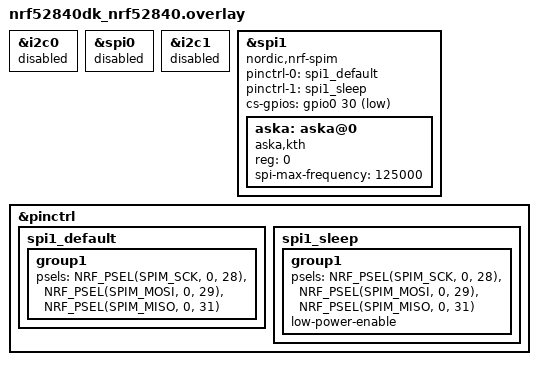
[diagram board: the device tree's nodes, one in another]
// To get started, press Ctrl+Space to bring up the completion menu and view the available nodes.

// You can also use the buttons in the sidebar to perform actions on nodes.
// Actions currently available include:

// * Enabling / disabling the node
// * Adding the bus to a bus
// * Removing the node
// * Connecting ADC channels

// For more help, browse the DeviceTree documentation at https://docs.zephyrproject.org/latest/guides/dts/index.html
// You can also visit the nRF DeviceTree extension documentation at https://docs.nordicsemi.com/bundle/nrf-connect-vscode/page/guides/ncs_configure_app.html#devicetree-support-in-the-extension

&i2c0 { status = "disabled";};
&spi0 { status = "disabled";};
&i2c1 { status = "disabled";}; 

&spi1 {
    compatible = "nordic,nrf-spim";
    status = "okay";
    pinctrl-0 = <&spi1_default>;
    pinctrl-1 = <&spi1_sleep>;
    pinctrl-names = "default", "sleep";
    cs-gpios = <&gpio0 30 GPIO_ACTIVE_LOW>;
        aska: aska@0 {
        compatible = "aska,kth";
        reg = <0>;
        spi-max-frequency = <125000>;
    };
};

&pinctrl {
    spi1_default: spi1_default {
        group1 {
            psels = <NRF_PSEL(SPIM_SCK, 0, 28)>,					 
                    <NRF_PSEL(SPIM_MOSI, 0, 29)>,
                    <NRF_PSEL(SPIM_MISO, 0, 31)>;
        };
    };
    spi1_sleep: spi1_sleep {
        group1 {
            psels = <NRF_PSEL(SPIM_SCK, 0, 28)>,
                    <NRF_PSEL(SPIM_MOSI, 0, 29)>,
                    <NRF_PSEL(SPIM_MISO, 0, 31)>;
            low-power-enable;
        };
    };
};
